# GBA register map
Vendor: Nintendo; Series: Game Boy; File version: 1.0
CPU: ARM7TDMI r4p1, little endian, no MPU, no FPU, I-cache, vendor SysTick, 0 interrupt priority bits
Registers are 16-bit, read-write, reset 0x0 unless marked. A register's access mark holds for its fields unless they carry their own. Offsets are from the block's base; [hi:lo] are bit positions; {n}, {i} and the like mark numbered series.

## Timer_Registers
Base 0x04000100
{0x0+4i} TM{i}CNT_L (i=0..3) — Timer {i} Counter/Reload
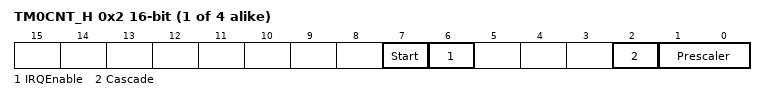
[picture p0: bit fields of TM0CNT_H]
{0x2+4i} TM{i}CNT_H (i=0..3) — Timer {i} Control
  [7] Start — Start / stop timer
  [6] IRQEnable — Generate interrupt on overflow
  [2] Cascade — Count-up from previous timer when set
  [1:0] Prescaler — Timer prescaler: 0=1, 1=64, 2=256, 3=1024 cycles

## Serial_Communication_(1)
Base 0x04000120
0x00 SIODATA32 32-bit — SIO Data (Normal-32bit Mode; shared with below)
0x00 SIOMULTI0 — SIO Data 0 (Parent) (Multi-Player Mode)
0x02 SIOMULTI1 — SIO Data 1 (1st Child) (Multi-Player Mode)
0x04 SIOMULTI2 — SIO Data 2 (2nd Child) (Multi-Player Mode)
0x06 SIOMULTI3 — SIO Data 3 (3rd Child) (Multi-Player Mode)
0x08 SIOCNT — SIO Control Register
0x0A SIOMLT_SEND — SIO Data (Local of MultiPlayer; shared below)
  [15:0] SIOMLTSend
0x0A SIODATA8 — SIO Data (Normal-8bit and UART Mode)

## Keypad_Input
Base 0x04000130
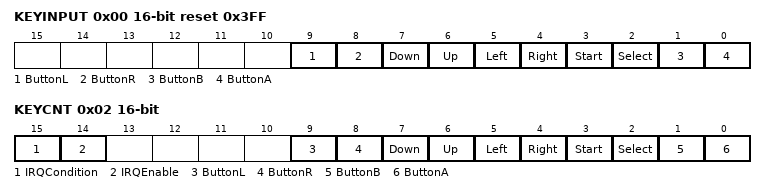
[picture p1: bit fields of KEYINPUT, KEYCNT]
0x00 KEYINPUT ro reset 0x3FF — Active-low state of all keypad buttons
  [9] ButtonL — Left shoulder button state; 0=pressed, 1=released
  [8] ButtonR — Right shoulder button state; 0=pressed, 1=released
  [7] Down — Down direction pad state; 0=pressed, 1=released
  [6] Up — Up direction pad state; 0=pressed, 1=released
  [5] Left — Left direction pad state; 0=pressed, 1=released
  [4] Right — Right direction pad state; 0=pressed, 1=released
  [3] Start — Start state; 0=pressed, 1=released
  [2] Select — Select state; 0=pressed, 1=released
  [1] ButtonB — Button B state; 0=pressed, 1=released
  [0] ButtonA — Button A state; 0=pressed, 1=released
    0=Pressed; 1=Released
0x02 KEYCNT — Configures the keypad IRQ condition
  [15] IRQCondition — 0=OR of selected keys, 1=AND of selected keys
    0=OR; 1=AND
  [14] IRQEnable — Enable keypad interrupt generation
  [9] ButtonL — Enable interrupt on L key
  [8] ButtonR — Enable interrupt on R key
  [7] Down — Enable interrupt on Down key
  [6] Up — Enable interrupt on Up key
  [5] Left — Enable interrupt on Left key
  [4] Right — Enable interrupt on Right key
  [3] Start — Enable interrupt on Start key
  [2] Select — Enable interrupt on Select key
  [1] ButtonB — Enable interrupt on B key
  [0] ButtonA — Enable interrupt on A key

## Serial_Communication_(2)
Base 0x04000134
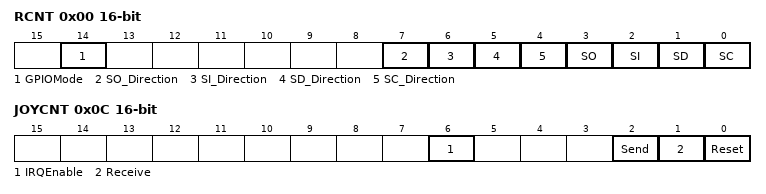
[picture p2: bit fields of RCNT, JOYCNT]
0x00 RCNT — General-purpose I/O and mode control
  [14] GPIOMode — General-purpose I/O mode enable
  [7] SO_Direction — SO pin direction; 0=input, 1=output
  [6] SI_Direction — SI pin direction; 0=input, 1=output
  [5] SD_Direction — SD pin direction; 0=input, 1=output
  [4] SC_Direction — SC pin direction; 0=input, 1=output
  [3] SO — SO data / direction
  [2] SI — SI data / direction
  [1] SD — SD data / direction
  [0] SC — SC data / direction
0x0C JOYCNT — Joy Bus control
  [6] IRQEnable — Enable Joy Bus interrupt
  [2] Send — Send complete
  [1] Receive — Receive complete
  [0] Reset — Device reset received
0x1C JOY_RECV 32-bit — SIO JOY Bus Receive Data
  [31:0] JoyReceive
0x20 JOY_TRANS 32-bit — SIO JOY Bus Transmit Data
  [31:0] JoyTransmit

## Interrupt,_Waitstate,_and_Power-Down_Control
Base 0x04000200
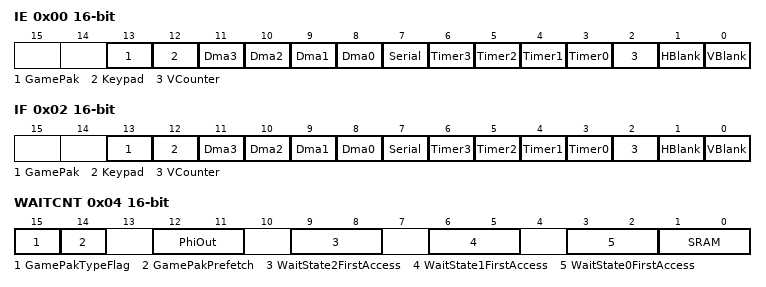
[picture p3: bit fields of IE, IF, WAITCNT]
0x00 IE — Interrupt Enable Register
  [13] GamePak — Game Pak (external IRQ source) interrupt enable
  [12] Keypad — Keypad interrupt enable
  [n+8] Dma{n} (n=0..3) — DMA {n} interrupt enable
  [7] Serial — Serial Communication interrupt enable
  [n+3] Timer{n} (n=0..3) — Timer {n} Overflow interrupt enable
  [2] VCounter — LCD V-Counter Match interrupt enable
  [1] HBlank — LCD H-Blank interrupt enable
  [0] VBlank — LCD V-Blank interrupt enable
0x02 IF — Interrupt Request Flags / IRQ Acknowledge
  [13] GamePak — Game Pak (external IRQ source) interrupt request; write 1 to acknowledge
  [12] Keypad — Keypad interrupt request; write 1 to acknowledge
  [n+8] Dma{n} (n=0..3) — DMA {n} interrupt request; write 1 to acknowledge
  [7] Serial — Serial Communication interrupt request; write 1 to acknowledge
  [n+3] Timer{n} (n=0..3) — Timer {n} Overflow interrupt request; write 1 to acknowledge
  [2] VCounter — LCD V-Counter Match interrupt request; write 1 to acknowledge
  [1] HBlank — LCD H-Blank interrupt request; write 1 to acknowledge
  [0] VBlank — LCD V-Blank interrupt request; write 1 to acknowledge
0x04 WAITCNT — Game Pak Waitstate Control
  [15] GamePakTypeFlag ro — Read-only Game Pak type signal: 0=GBA, 1=CGB.
    0=GBA; 1=CGBMode
  [14] GamePakPrefetch — Enable the Game Pak prefetch buffer.
  [12:11] PhiOut — External cartridge clock output selection.
    0=Disabled
  [9:8] WaitState2FirstAccess — Game Pak wait-state 2 first-access timing.
    0=4
  [6:5] WaitState1FirstAccess — Game Pak wait-state 1 first-access timing.
    0=4
  [3:2] WaitState0FirstAccess — Game Pak wait-state 0 first-access timing.
    0=4
  [1:0] SRAM Wait Control — Game Pak SRAM access wait-state selection.
    0=4
0x08 IME — Interrupt Master Enable Register
  [0] IRQDisable — Master interrupt enable; forwards enabled IRQ sources when set.
    0=Disable All; 1=See IE register
0x100 POSTFLG 8-bit reset 0x1 — Undocumented POST flag used during cartridge boot and startup handshake
  [7:0] POSTFLG — POST boot flag; read and written by startup ROM code for cartridge/boot handshake
0x101 HALTCNT 8-bit wo — Undocumented low-power halt control register; write 0x00 to enter halt, 0x01 to stop the CPU
  [7] PowerDownMode — Power-down mode: 0=Halt, 1=Stop.
